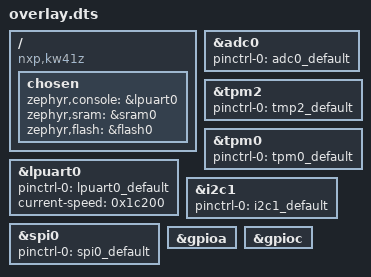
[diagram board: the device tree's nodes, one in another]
/ {
	compatible = "nxp,kw41z", "nxp,mkw41z4";
	chosen {
		zephyr,console = &lpuart0;
		zephyr,sram = &sram0;
		zephyr,flash = &flash0;
	};
};
&adc0{
	status = "okay";
	pinctrl-0 = < &adc0_default >;
	pinctrl-names = "default";
};
&tpm2{
	status = "okay";
	pinctrl-0 = < &tmp2_default >;
	pinctrl-names = "default";
};
&tpm0{
	status = "okay";
	pinctrl-0 = < &tpm0_default >;
	pinctrl-names = "default";
};
&lpuart0{
	status = "okay";
	pinctrl-0 = < &lpuart0_default >;
	pinctrl-names = "default";
	current-speed = < 0x1c200 >;
};
&i2c1{
	status = "okay";
	pinctrl-0 = < &i2c1_default >;
	pinctrl-names = "default";
};
&spi0{
	status = "okay";
	pinctrl-0 = < &spi0_default >;
	pinctrl-names = "default";
};
&gpioa{
	status = "okay";
};
&gpioc{
	status = "okay";
};
